# R7FA6M5BH register map
Vendor: Renesas Electronics Corporation; Series: RA6; File version: 1.20.01
CPU: CM33 r0p4, little endian, MPU, FPU, VTOR, 4 interrupt priority bits, 96 interrupts
Registers are 32-bit, read-write, reset 0x0 unless marked. A register's access mark holds for its fields unless they carry their own. Offsets are from the block's base; [hi:lo] are bit positions; {n}, {i} and the like mark numbered series; 'fields as' and 'values as' point back to an identical list.

## POEG — Port Output Enable Module for GPT
Base 0x4008A000
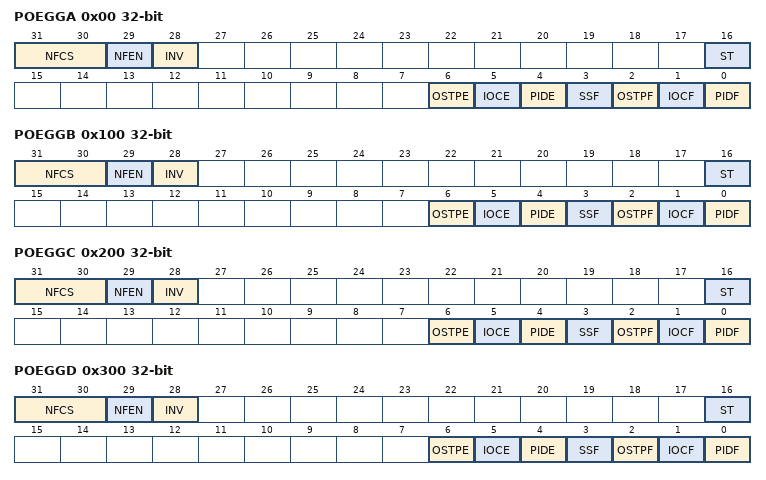
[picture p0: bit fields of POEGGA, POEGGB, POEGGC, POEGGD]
0x00 POEGGA — POEG Group A Setting Register
  [31:30] NFCS — Noise Filter Clock Select
    0=Sample GTETRGn pin input level three times every PCLKB; 1=Sample GTETRGn pin input level three times every PCLKB/8; 2=Sample GTETRGn pin input level three times every PCLKB/32; 3=Sample GTETRGn pin input level three times every PCLKB/128
  [29] NFEN — Noise Filter Enable
    0=Disable noise filtering; 1=Enable noise filtering
  [28] INV — GTETRGn Input Reverse
    0=Input GTETRGn as-is; 1=Input GTETRGn in reverse
  [16] ST ro — GTETRGn Input Status Flag
    0=GTETRGn input after filtering was 0; 1=GTETRGn input after filtering was 1
  [6] OSTPE — Oscillation Stop Detection Enable
    0=Disable output-disable requests from oscillation stop detection; 1=Enable output-disable requests from oscillation stop detection
  [5] IOCE — Enable for GPT Output-Disable Request
    0=Disable output-disable requests from GPT; 1=Enable output-disable requests from GPT
  [4] PIDE — Port Input Detection Enable
    0=Disable output-disable requests from the GTETRGn pins; 1=Enable output-disable requests from the GTETRGn pins
  [3] SSF — Software Stop Flag
    0=No output-disable request from software occurred; 1=Output-disable request from software occurred
  [2] OSTPF — Oscillation Stop Detection Flag
    0=No output-disable request from oscillation stop detection occurred; 1=Output-disable request from oscillation stop detection occurred
  [1] IOCF — Detection Flag for GPT Output-Disable Request
    0=No output-disable request from GPT occurred; 1=Output-disable request from GPT occurred
  [0] PIDF — Port Input Detection Flag
    0=No output-disable request from the GTETRGn pin occurred; 1=Output-disable request from the GTETRGn pin occurred
0x100 POEGGB — POEG Group B Setting Register
  fields as POEGGA
0x200 POEGGC — POEG Group C Setting Register
  fields as POEGGA
0x300 POEGGD — POEG Group D Setting Register
  fields as POEGGA

## IIC0WU — Inter-Integrated Circuit 0 Wake-up Unit
Base 0x4009F014
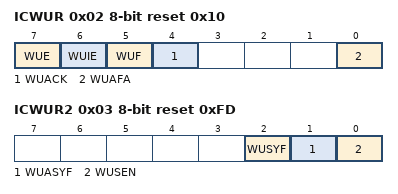
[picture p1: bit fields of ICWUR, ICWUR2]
0x02 ICWUR 8-bit reset 0x10 — I2C Bus Wakeup Unit Register
  [7] WUE — Wakeup Function Enable
    0=Disable wakeup function; 1=Enable wakeup function
  [6] WUIE — Wakeup Interrupt Request Enable
    0=Disable wakeup interrupt request (IIC0_WUI); 1=Enable wakeup interrupt request (IIC0_WUI)
  [5] WUF — Wakeup Event Occurrence Flag
    0=Slave address not matching during wakeup; 1=Slave address matching during wakeup
  [4] WUACK — ACK Bit for Wakeup Mode
  [0] WUAFA — Wakeup Analog Filter Additional Selection
    0=Do not add the wakeup analog filter; 1=Add the wakeup analog filter
0x03 ICWUR2 8-bit reset 0xFD — I2C Bus Wakeup Unit Register 2
  [2] WUSYF ro — Wakeup Function Synchronous Operation Status Flag
    0=IIC asynchronous circuit enable condition; 1=IIC synchronous circuit enable condition
  [1] WUASYF ro — Wakeup Function Asynchronous Operation Status Flag
    0=IIC synchronous circuit enable condition; 1=IIC asynchronous circuit enable condition
  [0] WUSEN — Wakeup Function Synchronous Enable
    0=IIC asynchronous circuit enable; 1=IIC synchronous circuit enable

## CTSU — Capacitive Touch Sensing Unit
Base 0x400D0000
0x00 CTSUCR0 8-bit — CTSU Control Register 0
0x01 CTSUCR1 8-bit — CTSU Control Register 1
0x02 CTSUSDPRS 8-bit — CTSU Synchronous Noise Reduction Setting Register
0x03 CTSUSST 8-bit — CTSU Sensor Stabilization Wait Control Register
0x04 CTSUMCH0 8-bit reset 0x1F — CTSU Measurement Channel Register 0
0x05 CTSUMCH1 8-bit ro reset 0x1F — CTSU Measurement Channel Register 1
{0x6+i} CTSUCHAC{i} 8-bit (i=0..2) — CTSU Channel Enable Control Register {i}
{0xB+i} CTSUCHTRC{i} 8-bit (i=0..2) — CTSU Channel Transmit/Receive Control Register {i}
0x10 CTSUDCLKC 8-bit — CTSU High-Pass Noise Reduction Control Register
0x11 CTSUST 8-bit — CTSU Status Register
0x12 CTSUSSC 16-bit — CTSU High-Pass Noise Reduction Spectrum Diffusion Control Register
  [11:8] CTSUSSDIV — CTSU Spectrum Diffusion Frequency Division Setting
0x14 CTSUSO0 16-bit — CTSU Sensor Offset Register 0
0x16 CTSUSO1 16-bit — CTSU Sensor Offset Register 1
0x18 CTSUSC 16-bit ro — CTSU Sensor Counter
0x1A CTSURC 16-bit ro — CTSU Reference Counter
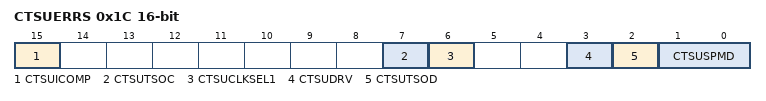
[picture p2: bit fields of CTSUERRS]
0x1C CTSUERRS 16-bit (reset mask 0x7FFF) — CTSU Error Status Register
  [15] CTSUICOMP ro — TSCAP Voltage Error Monitor
    0=Normal TSCAP voltage; 1=Abnormal TSCAP voltage
  [7] CTSUTSOC — Calibration Setting 2
    0=Capacitance measurement mode; 1=Calibration setting 2
  [6] CTSUCLKSEL1 — Calibration Setting 3
    0=Capacitance measurement mode; 1=Calibration setting 3
  [3] CTSUDRV — Calibration Setting 1
    0=Capacitance measurement mode; 1=Calibration setting 1
  [2] CTSUTSOD — TS Pin Fixed Output
    0=Capacitance measurement mode; 1=TS pins are forced to be high or low
  [1:0] CTSUSPMD — Calibration Mode
    0=Capacitance measurement mode; 2=Calibration mode; other=Others (Seting prohibited)
0x20 CTSUTRMR 8-bit reset not defined — CTSU Reference Current Calibration Register
